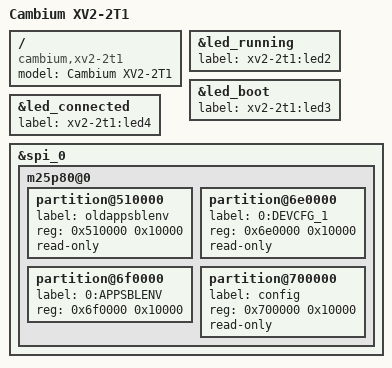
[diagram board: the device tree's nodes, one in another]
// SPDX-License-Identifier: (GPL-2.0+ OR BSD-3-Clause)
/*
 * Cambium XV2-2T1 device tree source
 *
 * The XV2-2T with 120-degree sector antennas, 11 dBi at 2.4 GHz and 13 dBi
 * at 5 GHz against the omni XV2-2T0's 5 and 9. The vendor's own device tree
 * for it differs from the 2T0's in nothing but the board SKU number (31
 * against 22), so everything but the model name and the LED labels is in
 * qcom-ipq6018-cambium-xv2-2t.dtsi. The antenna gain is what earns it its
 * own board name: 03_wireless caps its transmit power.
 *
 * Copyright (c) 2019-2021 The Linux Foundation. All rights reserved.
 */

/dts-v1/;

#include "qcom-ipq6018-cambium-xv2-2t.dtsi"

/ {
	model = "Cambium XV2-2T1";
	compatible = "cambium,xv2-2t1", "qcom,ipq6018-ap-cp01", "qcom,ipq6018";
};

&led_running {
	label = "xv2-2t1:led2";
};

&led_boot {
	label = "xv2-2t1:led3";
};

&led_connected {
	label = "xv2-2t1:led4";
};

/*
 * The XV2-2T1 ships a different NOR map from the XV2-2T0, so the table
 * inherited from the .dtsi is wrong here in one load-bearing place: this
 * board's MIBIB has 23 entries where the 2T0 has 20, and the U-Boot
 * environment moved. 0x510000 still exists but is a stale copy the
 * bootloader no longer reads (its contents date from before the unit
 * shipped), and stock's own fw_env.config points at 0x6f0000.
 *
 * Declaring the inherited offset would make fw_setenv write the dead
 * copy: the write would succeed, a readback would agree with itself,
 * and U-Boot would never see the new bootcmd - a silent non-install
 * rather than a visible failure. Verified against this unit's
 * /sys/class/mtd offsets and a full 16 MB flash dump.
 */
&spi_0 {
	m25p80@0 {
		partition@510000 {
			label = "oldappsblenv";
			reg = <0x510000 0x10000>;
			read-only;
		};

		partition@6e0000 {
			label = "0:DEVCFG_1";
			reg = <0x6e0000 0x10000>;
			read-only;
		};

		partition@6f0000 {
			label = "0:APPSBLENV";
			reg = <0x6f0000 0x10000>;
		};

		partition@700000 {
			label = "config";
			reg = <0x700000 0x10000>;
			read-only;
		};
	};
};
